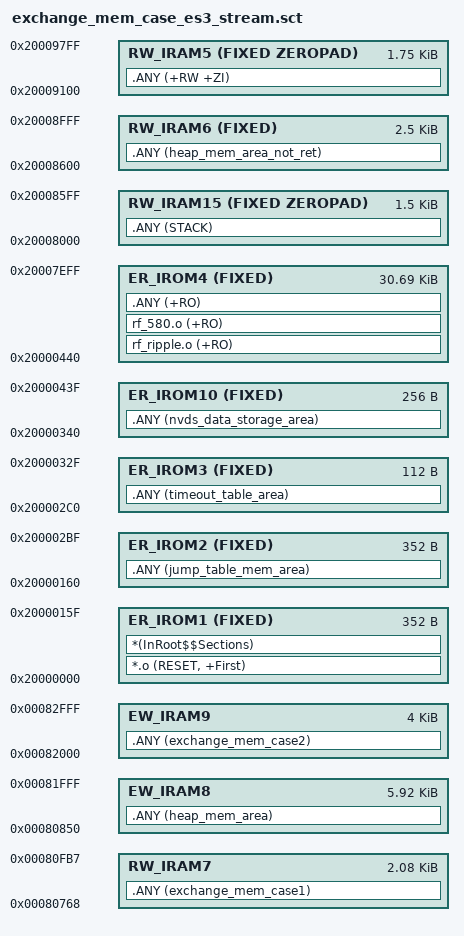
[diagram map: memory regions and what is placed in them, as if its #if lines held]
#! armcc -E -I./

#include "da14580_config.h"

; *************************************************************
; *** Scatter-Loading Description File generated by uVision ***
; *************************************************************

ER_IROM1 0x20000000 {  ; load region size_region
  ER_IROM1 0x20000000 FIXED 0x00000160  {  ; load address = execution address
   *.o (RESET, +First)
   *(InRoot$$Sections)
  }
}
 
ER_IROM2  0x20000160 {
ER_IROM2 0x20000160 FIXED 0x00160  {
   .ANY (jump_table_mem_area) 
	
  }
}

ER_IROM3 0x200002C0 {
 ER_IROM3 0x200002C0 FIXED 0x070  {
   .ANY (timeout_table_area)
  }
}

ER_IROM10 0x20000340 {
 ER_IROM10 0x20000340 FIXED 0x0100  {
   .ANY (nvds_data_storage_area)
  }
}

ER_IROM4  0x20000440 {
ER_IROM4 0x20000440 FIXED 0x7ac0  {
    rf_ripple.o (+RO)
	rf_580.o (+RO)
	.ANY (+RO)   	
  }
}  

ER_IRAM15  0x20008000 {
RW_IRAM15 0x20008000 FIXED ZEROPAD 0x00000600 {  ; RW data
   .ANY (STACK)
  }
}

#if DEVELOPMENT__NO_OTP
ER_IRAM5 0x20009100 {  ; RW data
RW_IRAM5 0x20009100 FIXED ZEROPAD 0x00000700   {  ; RW data
   .ANY (+RW +ZI)
  }
  }
#endif

ER_IRAM6 0x20008600 {
RW_IRAM6 0x20008600 FIXED 0x0000a00  {
   .ANY (heap_mem_area_not_ret)    
 }
}

ER_RET_RAM  0x00080768 NOCOMPRESS 0x2898 {
RW_IRAM7 0x000080768 0x00000850  {
   .ANY (exchange_mem_case1) 
;   rand.o(+RW,+Last)
 }

EW_IRAM8 0x000080850 0x000017B0  {
    .ANY (heap_mem_area)
}
EW_IRAM9 0x000082000 0x00001000  {
   .ANY (exchange_mem_case2) 
}
}

